# DPHY_RX0_VBUS2APB_WRAP_VBUSP_K3_DPHY_RX register map
Vendor: Texas Instruments
Registers are 32-bit, access per field, reset 0x0 unless marked. A register's access mark holds for its fields unless they carry their own. Offsets are as the file gives them; [hi:lo] are bit positions; {n}, {i} and the like mark numbered series.

## DPHY_RX0_VBUS2APB_WRAP_VBUSP_K3_DPHY_RX (part 2 of 2)
{0x0+4i} DPHY_RX_VBUS2APB_CMN0_CMN_ANA_TBIT{i} rw (i=0..2) — CMN_ANA_TBIT{i}
  [31:0] ANA_TBIT{i} — Analog Test register {i}
0x0C DPHY_RX_VBUS2APB_CMN0_CMN_ANA_TBIT3 ro — CMN_ANA_TBIT3
  [31:0] ANA_TBIT3 — RESERVED
0x10 DPHY_RX_VBUS2APB_CMN0_CMN_ANA_TBIT4 rw — CMN_ANA_TBIT4
  [31:0] ANA_TBIT4 — Analog Test register 4
0x14 DPHY_RX_VBUS2APB_CMN0_CMN_ANA_TBIT5 — CMN_ANA_TBIT5
  [7:0] ANA_TBIT5 rw — Analog Test register 5
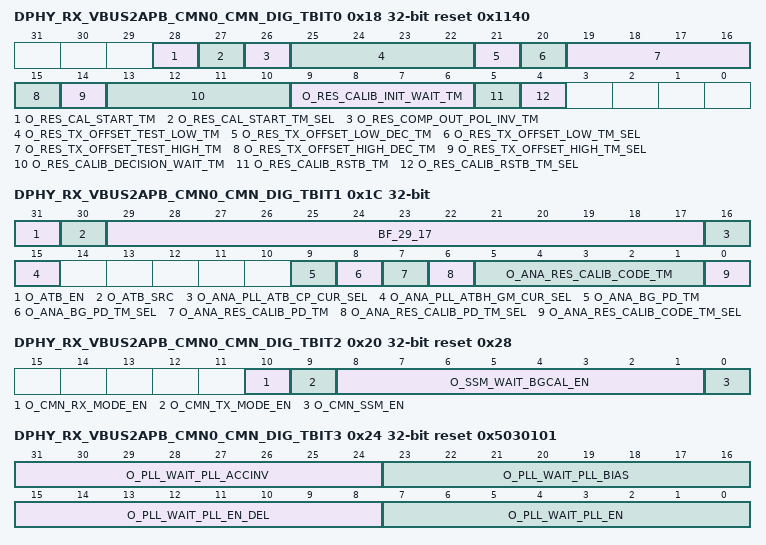
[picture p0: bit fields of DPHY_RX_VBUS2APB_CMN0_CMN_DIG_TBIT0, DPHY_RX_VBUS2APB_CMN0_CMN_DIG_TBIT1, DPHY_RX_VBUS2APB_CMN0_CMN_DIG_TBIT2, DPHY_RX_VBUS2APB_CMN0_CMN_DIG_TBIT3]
0x18 DPHY_RX_VBUS2APB_CMN0_CMN_DIG_TBIT0 reset 0x1140 — CMN_DIG_TBIT0
  [28] O_RES_CAL_START_TM rw — res_cal_start in test mode
  [27] O_RES_CAL_START_TM_SEL rw — res_cal_start select from test_mode
  [26] O_RES_COMP_OUT_POL_INV_TM rw — Invert polarity for resistor calib comparator output
  [25:22] O_RES_TX_OFFSET_TEST_LOW_TM rw — o_res_tx_offset_test_low_TM - Res calib manipulation code for res calib code low
  [21] O_RES_TX_OFFSET_LOW_DEC_TM rw — o_res_tx_offset_low_dec_TM asserted - Perform increment manipulation on res calib code if o_res_tx_offset_low_TM_sel is asserted
  [20] O_RES_TX_OFFSET_LOW_TM_SEL rw — o_res_tx_offset_low_TM_sel asserted - Enable offset manipulation for res calib code low
  [19:16] O_RES_TX_OFFSET_TEST_HIGH_TM rw — o_res_tx_offset_test_high_TM - Res calib manipulation code for res calib code high
  [15] O_RES_TX_OFFSET_HIGH_DEC_TM rw — o_res_tx_offset_high_dec_TM asserted - Perform increment manipulation on res calib code if o_res_tx_offset_high_TM_sel is asserted
  [14] O_RES_TX_OFFSET_HIGH_TM_SEL rw — o_res_tx_offset_high_TM_sel asserted - Enable offset manipulation for res calib code high
  [13:10] O_RES_CALIB_DECISION_WAIT_TM rw — res_calib decision wait time
  [9:6] O_RES_CALIB_INIT_WAIT_TM rw — res_calib initial wait time
  [5] O_RES_CALIB_RSTB_TM rw — w_res_calib_rstb value in testmode
  [4] O_RES_CALIB_RSTB_TM_SEL rw — w_res_calib_rstb select from test_mode
0x1C DPHY_RX_VBUS2APB_CMN0_CMN_DIG_TBIT1 — CMN_DIG_TBIT1
  [31] O_ATB_EN rw — ATB probing enabled
  [30] O_ATB_SRC rw — Select IO for atb probing
  [29:17] BF_29_17 rw
  [16] O_ANA_PLL_ATB_CP_CUR_SEL rw
  [15] O_ANA_PLL_ATBH_GM_CUR_SEL rw
  [9] O_ANA_BG_PD_TM rw — o_ana_bg_pd value in testmode
  [8] O_ANA_BG_PD_TM_SEL rw — o_ana_bg_pd select from test_mode
  [7] O_ANA_RES_CALIB_PD_TM rw — o_ana_res_calib_pd value in testmode
  [6] O_ANA_RES_CALIB_PD_TM_SEL rw — o_ana_res_calib_pd select from test_mode
  [5:1] O_ANA_RES_CALIB_CODE_TM rw — o_ana_res_calib_code value in test_mode
  [0] O_ANA_RES_CALIB_CODE_TM_SEL rw — o_ana_res_calib_code select from test_mode
0x20 DPHY_RX_VBUS2APB_CMN0_CMN_DIG_TBIT2 reset 0x28 — CMN_DIG_TBIT2
  [10] O_CMN_RX_MODE_EN rw — Enable CMN RX related StateMachines
  [9] O_CMN_TX_MODE_EN rw — Enable CMN TX related StateMachines
  [8:1] O_SSM_WAIT_BGCAL_EN rw — Wait time for Calibrations enable after bandgap is enabled [in us]
  [0] O_CMN_SSM_EN rw — Enable CMN startup state machine
0x24 DPHY_RX_VBUS2APB_CMN0_CMN_DIG_TBIT3 rw reset 0x5030101 — CMN_DIG_TBIT3
  [31:24] O_PLL_WAIT_PLL_ACCINV — Wait time in pll_accinv [in us]
  [23:16] O_PLL_WAIT_PLL_BIAS — Wait time in pll_bias [in us]
  [15:8] O_PLL_WAIT_PLL_EN_DEL — Wait time in pll_en_del [in us]
  [7:0] O_PLL_WAIT_PLL_EN — Wait time in PLL en [in us]
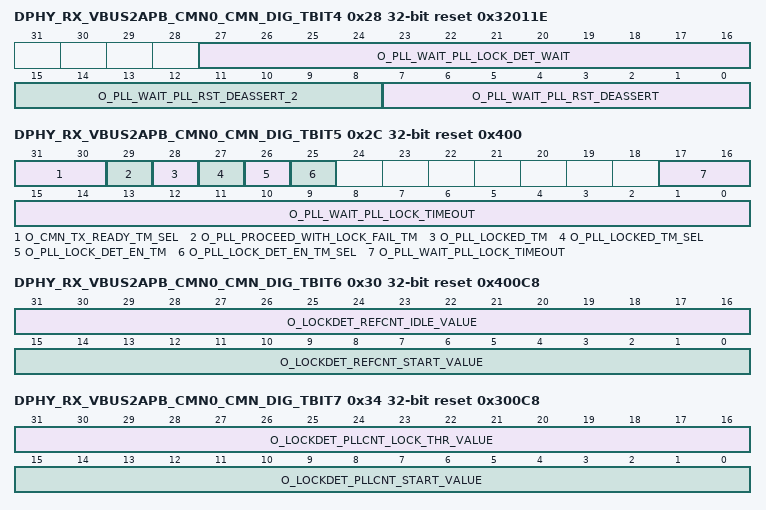
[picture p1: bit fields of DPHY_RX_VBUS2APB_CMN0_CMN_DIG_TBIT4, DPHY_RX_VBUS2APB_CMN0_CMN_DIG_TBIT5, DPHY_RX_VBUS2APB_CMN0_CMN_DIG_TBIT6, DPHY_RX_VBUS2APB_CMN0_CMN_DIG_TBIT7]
0x28 DPHY_RX_VBUS2APB_CMN0_CMN_DIG_TBIT4 reset 0x32011E — CMN_DIG_TBIT4
  [27:16] O_PLL_WAIT_PLL_LOCK_DET_WAIT rw — Wait time in pll_lock_det_wait [in us]
  [15:8] O_PLL_WAIT_PLL_RST_DEASSERT_2 rw — Wait time in pll_rst_deassert_2ndset [in us]
  [7:0] O_PLL_WAIT_PLL_RST_DEASSERT rw — Wait time in pll_rst_deassert [in us]
0x2C DPHY_RX_VBUS2APB_CMN0_CMN_DIG_TBIT5 reset 0x400
  [31:30] O_CMN_TX_READY_TM_SEL rw — ATB probing enabled
  [29] O_PLL_PROCEED_WITH_LOCK_FAIL_TM rw — o_ana_pll_atb_cp_cur_sel
  [28] O_PLL_LOCKED_TM rw — Forced value of pll_locked going to fsm = 1
  [27] O_PLL_LOCKED_TM_SEL rw — pll_locked going to fsm forced from test registers
  [26] O_PLL_LOCK_DET_EN_TM rw — Forced value of pll_lock_det_en = 1
  [25] O_PLL_LOCK_DET_EN_TM_SEL rw — pll_lock_det_en forced from test registers
  [17:0] O_PLL_WAIT_PLL_LOCK_TIMEOUT rw — Wait time for pll_lock_timeout [in us]
0x30 DPHY_RX_VBUS2APB_CMN0_CMN_DIG_TBIT6 rw reset 0x400C8 — CMN_DIG_TBIT6
  [31:16] O_LOCKDET_REFCNT_IDLE_VALUE — refcnt idle value for PLL lock detect module
  [15:0] O_LOCKDET_REFCNT_START_VALUE — refcnt start value for PLL lock detect module
0x34 DPHY_RX_VBUS2APB_CMN0_CMN_DIG_TBIT7 rw reset 0x300C8 — CMN_DIG_TBIT7
  [31:16] O_LOCKDET_PLLCNT_LOCK_THR_VALUE — pllcnt lock threshold value for PLL lock detect module
  [15:0] O_LOCKDET_PLLCNT_START_VALUE — pllcnt start value for PLL lock detect module
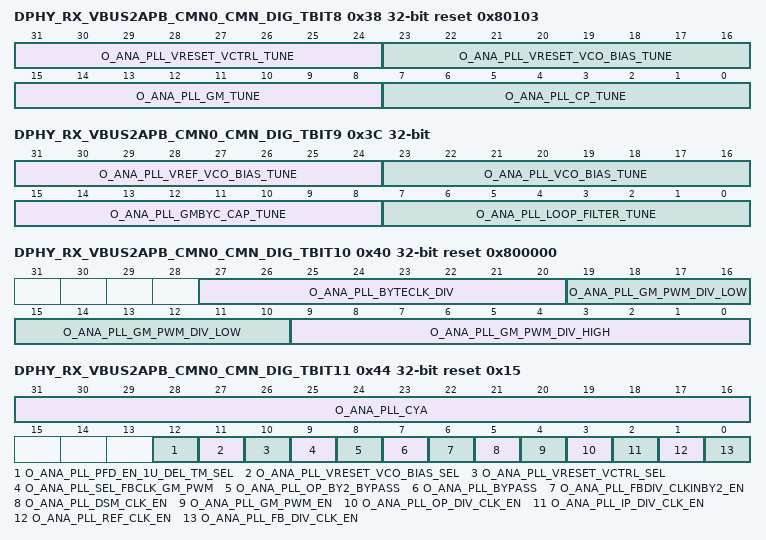
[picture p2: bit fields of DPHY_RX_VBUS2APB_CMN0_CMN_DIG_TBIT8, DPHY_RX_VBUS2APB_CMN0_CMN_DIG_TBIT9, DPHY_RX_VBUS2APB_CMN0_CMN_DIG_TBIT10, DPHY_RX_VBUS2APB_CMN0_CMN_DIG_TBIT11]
0x38 DPHY_RX_VBUS2APB_CMN0_CMN_DIG_TBIT8 rw reset 0x80103 — CMN_DIG_TBIT8
  [31:24] O_ANA_PLL_VRESET_VCTRL_TUNE — unconnected, intended for vreset_vctrl[CP output] progrmmability
  [23:16] O_ANA_PLL_VRESET_VCO_BIAS_TUNE — Programmability for vco bias[gmbyc] initial voltage
  [15:8] O_ANA_PLL_GM_TUNE — gm tune value for PLL
  [7:0] O_ANA_PLL_CP_TUNE — Charge Pump Tune value for PLL
0x3C DPHY_RX_VBUS2APB_CMN0_CMN_DIG_TBIT9 rw — CMN_DIG_TBIT9
  [31:24] O_ANA_PLL_VREF_VCO_BIAS_TUNE — Tuning Control for reference vco bias in PLL
  [23:16] O_ANA_PLL_VCO_BIAS_TUNE — Tuning Control for PLL vco bias
  [15:8] O_ANA_PLL_GMBYC_CAP_TUNE — gmbyc tune value for PLL
  [7:0] O_ANA_PLL_LOOP_FILTER_TUNE — Tuning Control for loop filter
0x40 DPHY_RX_VBUS2APB_CMN0_CMN_DIG_TBIT10 reset 0x800000 — CMN_DIG_TBIT10
  [27:20] O_ANA_PLL_BYTECLK_DIV rw — Byteclk divider value
  [19:10] O_ANA_PLL_GM_PWM_DIV_LOW rw — Low division value setting for the gm PWM control divider
  [9:0] O_ANA_PLL_GM_PWM_DIV_HIGH rw — High division value setting for the gm PWM control divider
0x44 DPHY_RX_VBUS2APB_CMN0_CMN_DIG_TBIT11 reset 0x15 — CMN_DIG_TBIT11
  [31:16] O_ANA_PLL_CYA rw — Drives pllda_cya going to ANA
  [12] O_ANA_PLL_PFD_EN_1U_DEL_TM_SEL rw — Testmode signal for selecting 1us delayed for pll_pfd_reset_n
  [11] O_ANA_PLL_VRESET_VCO_BIAS_SEL rw — vreset_vctrl_gmbyc is set inside the pll_vreset_gen
  [10] O_ANA_PLL_VRESET_VCTRL_SEL rw — vreset_vctrl is set to ground inside the pll_vreset_gen
  [9] O_ANA_PLL_SEL_FBCLK_GM_PWM rw — Enable mode to use feedback clock as the PWM control input for the gm stage
  [8] O_ANA_PLL_OP_BY2_BYPASS rw — Mode to bypass the divide by 2 in the PLL output which generates clk_bit and clk_bitb
  [7] O_ANA_PLL_BYPASS rw — Bypass PLL and pass refclk as output
  [6] O_ANA_PLL_FBDIV_CLKINBY2_EN rw — Enable division by 2 on the feedback divider input clock
  [5] O_ANA_PLL_DSM_CLK_EN rw — Enable for dsm clock output to digital
  [4] O_ANA_PLL_GM_PWM_EN rw — Enable PWM control of the gm, else it will operate in the continuous mode
  [3] O_ANA_PLL_OP_DIV_CLK_EN rw — Enable for op divider clock output to digital
  [2] O_ANA_PLL_IP_DIV_CLK_EN rw — Enable for ip divider output to digital
  [1] O_ANA_PLL_REF_CLK_EN rw — enables refclk to PLL
  [0] O_ANA_PLL_FB_DIV_CLK_EN rw — Enable for feedback clock output to digital
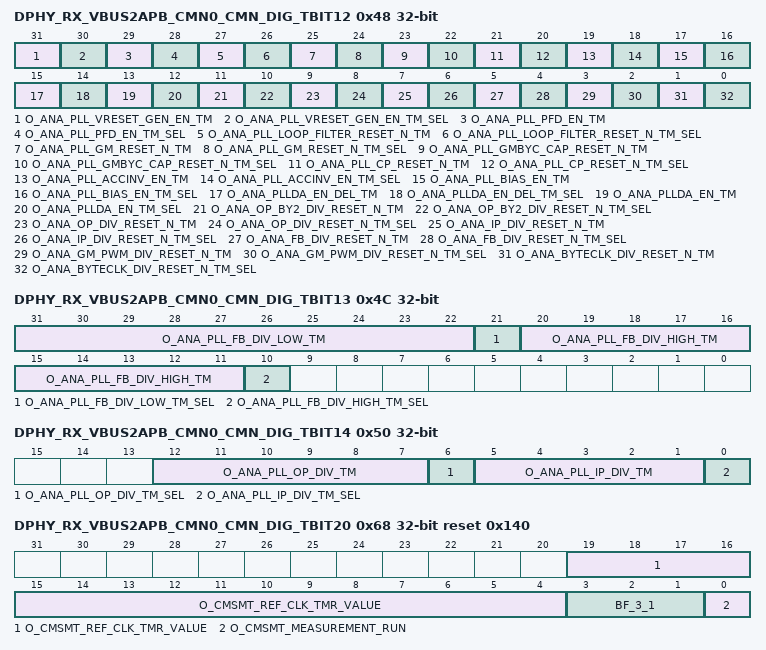
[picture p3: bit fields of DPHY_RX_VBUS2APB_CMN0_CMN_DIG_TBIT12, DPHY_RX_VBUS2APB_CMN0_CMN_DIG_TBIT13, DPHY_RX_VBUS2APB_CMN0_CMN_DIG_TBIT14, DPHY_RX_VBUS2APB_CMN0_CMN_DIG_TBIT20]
0x48 DPHY_RX_VBUS2APB_CMN0_CMN_DIG_TBIT12 rw — CMN_DIG_TBIT12
  [31] O_ANA_PLL_VRESET_GEN_EN_TM — Forced value of pll_vreset_gen_en = 1
  [30] O_ANA_PLL_VRESET_GEN_EN_TM_SEL — pll_vreset_gen_en forced from test registers
  [29] O_ANA_PLL_PFD_EN_TM — Forced value of pllda_pfd_en = 1
  [28] O_ANA_PLL_PFD_EN_TM_SEL — pllda_pfd_en forced from test registers
  [27] O_ANA_PLL_LOOP_FILTER_RESET_N_TM — Forced value of pll_loop_filter_reset_n = 1
  [26] O_ANA_PLL_LOOP_FILTER_RESET_N_TM_SEL — pll_loop_filter_reset_n is drivne from test registers
  [25] O_ANA_PLL_GM_RESET_N_TM — Forced value of pll_gm_reset_n = 1
  [24] O_ANA_PLL_GM_RESET_N_TM_SEL — pll_gm_reset_n is drivne from test registers
  [23] O_ANA_PLL_GMBYC_CAP_RESET_N_TM — Forced value of pll_gmbyc_cap_reset_n = 1
  [22] O_ANA_PLL_GMBYC_CAP_RESET_N_TM_SEL — pll_gmbyc_cap_reset_n is drivne from test registers
  [21] O_ANA_PLL_CP_RESET_N_TM — Forced value of pll_cp_reset_n = 1
  [20] O_ANA_PLL_CP_RESET_N_TM_SEL — pll_cp_reset_n is drivne from test registers
  [19] O_ANA_PLL_ACCINV_EN_TM — Forced value of pllda_accinv = 1
  [18] O_ANA_PLL_ACCINV_EN_TM_SEL — pllda_accinv forced from test registers
  [17] O_ANA_PLL_BIAS_EN_TM — Forced value of pllda_bias_en = 1
  [16] O_ANA_PLL_BIAS_EN_TM_SEL — pllda_bias_en forced from test registers
  [15] O_ANA_PLLDA_EN_DEL_TM — Forced value of pllda_en_del = 1
  [14] O_ANA_PLLDA_EN_DEL_TM_SEL — pllda_en_del forced from test registers
  [13] O_ANA_PLLDA_EN_TM — Forced value of pllda_en_del = 1
  [12] O_ANA_PLLDA_EN_TM_SEL — pllda_en_del forced from test registers
  [11] O_ANA_OP_BY2_DIV_RESET_N_TM — Forced valu of pllda_op_by2_div_reset_n = 1
  [10] O_ANA_OP_BY2_DIV_RESET_N_TM_SEL — pllda_op_by2_div_reset_n forced from test registers
  [9] O_ANA_OP_DIV_RESET_N_TM — Forced value of pllda_op_div_reset_n = 1
  [8] O_ANA_OP_DIV_RESET_N_TM_SEL — pllda_op_div_reset_n forced from test registers
  [7] O_ANA_IP_DIV_RESET_N_TM — Forced value of pllda_ip_div_reset_n = 1
  [6] O_ANA_IP_DIV_RESET_N_TM_SEL — pllda_ip_div_reset_n forced from test registers
  [5] O_ANA_FB_DIV_RESET_N_TM — Forced value of pllda_fb_div_reset_n = 1
  [4] O_ANA_FB_DIV_RESET_N_TM_SEL — pllda_fb_div_reset_n forced from test registers
  [3] O_ANA_GM_PWM_DIV_RESET_N_TM — Forced value of pllda_gm_pwm_div_reset_n = 1
  [2] O_ANA_GM_PWM_DIV_RESET_N_TM_SEL — pllda_gm_pwm_div_reset_n forced from test registers
  [1] O_ANA_BYTECLK_DIV_RESET_N_TM — Forced value of pllda_byteclk_div_reset_n = 1
  [0] O_ANA_BYTECLK_DIV_RESET_N_TM_SEL — pllda_byteclk_div_reset_n forced from test registers
0x4C DPHY_RX_VBUS2APB_CMN0_CMN_DIG_TBIT13 — CMN_DIG_TBIT13
  [31:22] O_ANA_PLL_FB_DIV_LOW_TM rw — forced value for pll_fb_div_clk_low
  [21] O_ANA_PLL_FB_DIV_LOW_TM_SEL rw — pll_fb_div_clk_low forced from test registers
  [20:11] O_ANA_PLL_FB_DIV_HIGH_TM rw — forced value for pll_fb_div_clk_high
  [10] O_ANA_PLL_FB_DIV_HIGH_TM_SEL rw — pll_fb_div_clk_high forced from test registers
0x50 DPHY_RX_VBUS2APB_CMN0_CMN_DIG_TBIT14 — CMN_DIG_TBIT14
  [12:7] O_ANA_PLL_OP_DIV_TM rw — forced value for op_div
  [6] O_ANA_PLL_OP_DIV_TM_SEL rw — op_div forced from test registers
  [5:1] O_ANA_PLL_IP_DIV_TM rw — forced value for ip_div
  [0] O_ANA_PLL_IP_DIV_TM_SEL rw — ip_div forced from test registers
0x68 DPHY_RX_VBUS2APB_CMN0_CMN_DIG_TBIT20 reset 0x140 — CMN_DIG_TBIT20
  [19:4] O_CMSMT_REF_CLK_TMR_VALUE rw — Number of refclk cycles required for clock measurement
  [3:1] BF_3_1 rw
  [0] O_CMSMT_MEASUREMENT_RUN rw — Enables clock measurement
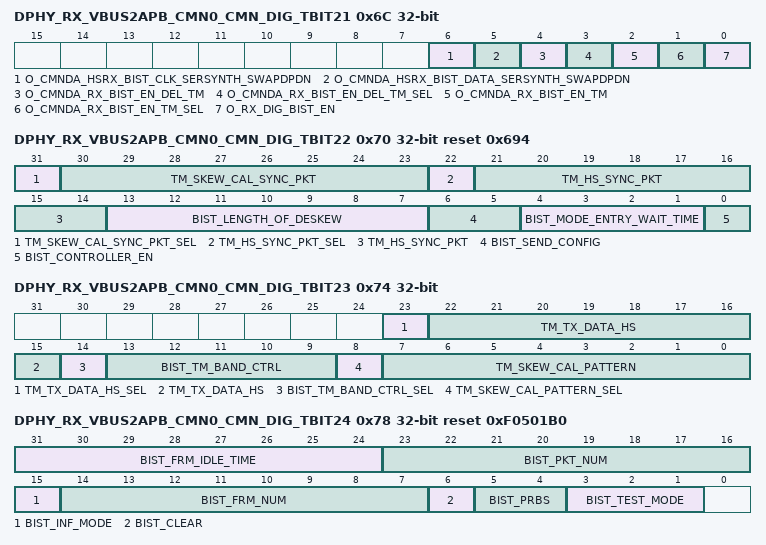
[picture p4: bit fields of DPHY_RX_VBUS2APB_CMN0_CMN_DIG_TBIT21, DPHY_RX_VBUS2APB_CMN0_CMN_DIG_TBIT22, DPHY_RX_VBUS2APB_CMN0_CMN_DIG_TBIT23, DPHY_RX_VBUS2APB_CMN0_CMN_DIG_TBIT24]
0x6C DPHY_RX_VBUS2APB_CMN0_CMN_DIG_TBIT21 — CMN_DIG_TBIT21
  [6] O_CMNDA_HSRX_BIST_CLK_SERSYNTH_SWAPDPDN rw — Enables swapping DP-DN lines for clock bist
  [5] O_CMNDA_HSRX_BIST_DATA_SERSYNTH_SWAPDPDN rw — Enables swapping DP-DN lines for data bist
  [4] O_CMNDA_RX_BIST_EN_DEL_TM rw — forced value of cmnda_rx_bist_en_del = 1
  [3] O_CMNDA_RX_BIST_EN_DEL_TM_SEL rw — cmnda_rx_bist_en_del driven from test registers
  [2] O_CMNDA_RX_BIST_EN_TM rw — forced value of cmnda_rx_bist_en = 1
  [1] O_CMNDA_RX_BIST_EN_TM_SEL rw — cmnda_rx_bist_en driven from test registers
  [0] O_RX_DIG_BIST_EN rw — BIST enable for digital
0x70 DPHY_RX_VBUS2APB_CMN0_CMN_DIG_TBIT22 rw reset 0x694 — BIST_CONFIG_REG1
  [31] TM_SKEW_CAL_SYNC_PKT_SEL — To send 'FF as Skew calibration sync packet
  [30:23] TM_SKEW_CAL_SYNC_PKT — desired skew calibration test sync packet
  [22] TM_HS_SYNC_PKT_SEL — To send 'B8 as HS sync packet
  [21:14] TM_HS_SYNC_PKT — desired HS test sync packet
  [13:7] BIST_LENGTH_OF_DESKEW — Length of deskew sequence In terms of us By default 13us of deskew sequence will be transmitted
  [6:5] BIST_SEND_CONFIG — Option of configuring what to send in BIST mose To send both deskew and HS data
  [4:1] BIST_MODE_ENTRY_WAIT_TIME — Once after giving bist_en signal to pattern generator, after these many number of BYTE clcok cycles pattern generation will start
  [0] BIST_CONTROLLER_EN — Enable BIST controller
0x74 DPHY_RX_VBUS2APB_CMN0_CMN_DIG_TBIT23 — BIST_CONFIG_REG2
  [23] TM_TX_DATA_HS_SEL rw — sends single test byte to sersynth, which is in &lt;
  [22:15] TM_TX_DATA_HS rw — Desired clock patetrn that can be sent using clk_sersynth
  [14] BIST_TM_BAND_CTRL_SEL rw — To take the default band control settigns by the design
  [13:9] BIST_TM_BAND_CTRL rw — Test mode band control setting to be done for BIST
  [8] TM_SKEW_CAL_PATTERN_SEL rw — To send 'AA as skew calibration pattern
  [7:0] TM_SKEW_CAL_PATTERN rw — desired skew calibration test sequence
0x78 DPHY_RX_VBUS2APB_CMN0_CMN_DIG_TBIT24 reset 0xF0501B0 — BIST_CONFIG_REG3
  [31:24] BIST_FRM_IDLE_TIME rw — BIST_FRM_IDLE time is time between the frames
  [23:16] BIST_PKT_NUM rw — BIST_PAK_NUM is number of packets that are to be transmitted per frame
  [15] BIST_INF_MODE rw — run infinite BIST mode
  [14:7] BIST_FRM_NUM rw — BIST_FRM_NUM is number of frames to be transmitted
  [6] BIST_CLEAR rw — clear the bist
  [5:4] BIST_PRBS rw — BIST PRBS MODE 9
  [3:1] BIST_TEST_MODE rw — PRBS mode
0x7C DPHY_RX_VBUS2APB_CMN0_CMN_DIG_TBIT25 reset 0x28 — BIST_CONFIG_REG4
  [11:0] BIST_RUN_LENGTH rw
0x80 DPHY_RX_VBUS2APB_CMN0_CMN_DIG_TBIT26 reset 0xA — BIST_CONFIG_REG5
  [7:0] BIST_IDLE_TIME rw
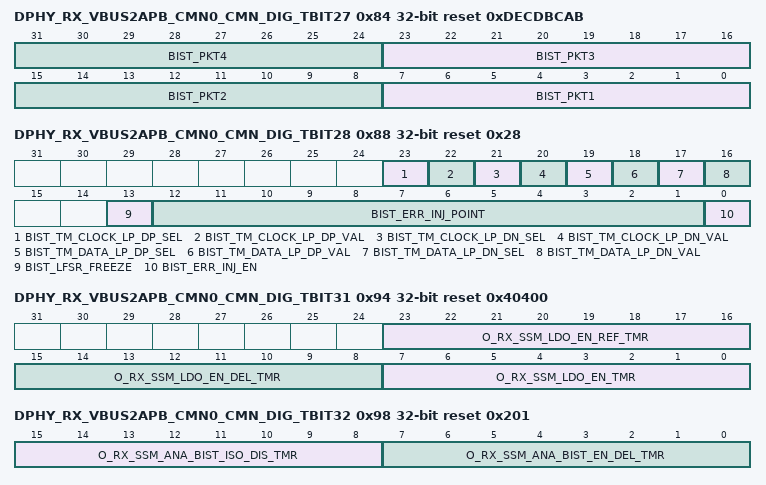
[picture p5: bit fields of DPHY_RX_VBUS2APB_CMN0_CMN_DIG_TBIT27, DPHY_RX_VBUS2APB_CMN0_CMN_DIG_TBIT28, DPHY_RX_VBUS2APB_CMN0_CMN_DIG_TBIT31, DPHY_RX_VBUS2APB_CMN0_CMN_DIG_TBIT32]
0x84 DPHY_RX_VBUS2APB_CMN0_CMN_DIG_TBIT27 rw reset 0xDECDBCAB — BIST_CONFIG_REG6
  [8n-1:8n-8] BIST_PKT{n} (n=1..4) — BIST_TEST_PAT{n}
0x88 DPHY_RX_VBUS2APB_CMN0_CMN_DIG_TBIT28 reset 0x28 — BIST_CONFIG_REG7
  [23] BIST_TM_CLOCK_LP_DP_SEL rw — Test mode selection bit to force clcok LP DP buffer to value from design
  [22] BIST_TM_CLOCK_LP_DP_VAL rw — Test mode clock LP DP buffer value is 0
  [21] BIST_TM_CLOCK_LP_DN_SEL rw — Test mode selection bit to force clcok LP DN buffer to value from design
  [20] BIST_TM_CLOCK_LP_DN_VAL rw — Test mode clock LP DN buffer value is 0
  [19] BIST_TM_DATA_LP_DP_SEL rw — Test mode selection bit to force data LP DP buffer to value from design
  [18] BIST_TM_DATA_LP_DP_VAL rw — Test mode data LP DP buffer value is 0
  [17] BIST_TM_DATA_LP_DN_SEL rw — Test mode selection bit to force data LP DN buffer to value from design
  [16] BIST_TM_DATA_LP_DN_VAL rw — Test mode data LP DN buffer value is 0
  [13] BIST_LFSR_FREEZE rw — Reset LFSR contents after every packet or frame
  [12:1] BIST_ERR_INJ_POINT rw — BIST_ERR_INJECT_POINT is where to inject the error in the packet
  [0] BIST_ERR_INJ_EN rw — Inject error in the BIST during the packet
0x94 DPHY_RX_VBUS2APB_CMN0_CMN_DIG_TBIT31 reset 0x40400 — CMN_DIG_TBIT31
  [23:16] O_RX_SSM_LDO_EN_REF_TMR rw — Wait time before enabling oscialltor calibration
  [15:8] O_RX_SSM_LDO_EN_DEL_TMR rw — wait time before enabling ldo_en_ref
  [7:0] O_RX_SSM_LDO_EN_TMR rw — Wait time between ldo_en and ldo_en_del
0x98 DPHY_RX_VBUS2APB_CMN0_CMN_DIG_TBIT32 reset 0x201 — CMN_DIG_TBIT32
  [15:8] O_RX_SSM_ANA_BIST_ISO_DIS_TMR rw — Wait time between Bist_en_del and disabling isolation
  [7:0] O_RX_SSM_ANA_BIST_EN_DEL_TMR rw — Wait time between Bist_en and bist_en_Del
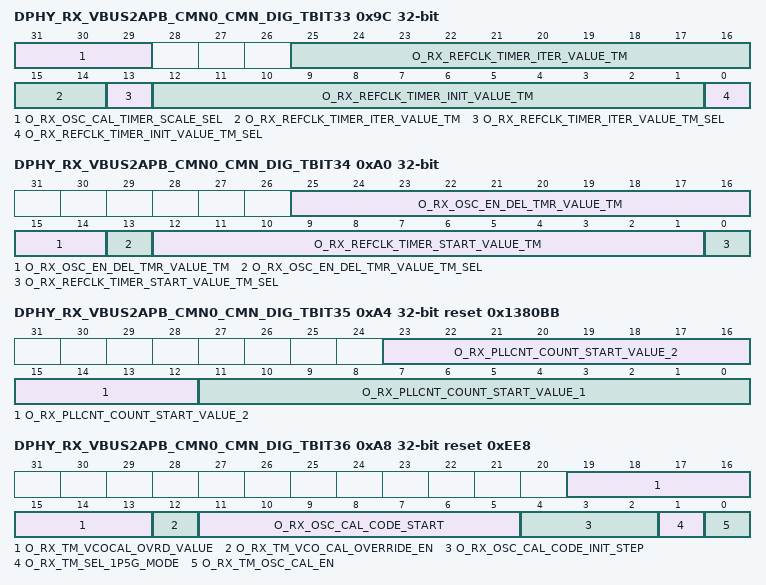
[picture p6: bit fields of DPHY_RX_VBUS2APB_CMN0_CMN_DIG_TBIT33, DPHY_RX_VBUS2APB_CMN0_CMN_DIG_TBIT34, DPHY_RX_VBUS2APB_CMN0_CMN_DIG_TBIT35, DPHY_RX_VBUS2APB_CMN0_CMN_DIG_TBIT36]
0x9C DPHY_RX_VBUS2APB_CMN0_CMN_DIG_TBIT33 — CMN_DIG_TBIT33
  [31:29] O_RX_OSC_CAL_TIMER_SCALE_SEL rw — Timer scale value for vco_count_window
  [25:14] O_RX_REFCLK_TIMER_ITER_VALUE_TM rw — Wait time required before enabling vco count window during iteration in test mode
  [13] O_RX_REFCLK_TIMER_ITER_VALUE_TM_SEL rw — refclk_timer_iter value driven from test register
  [12:1] O_RX_REFCLK_TIMER_INIT_VALUE_TM rw — Wait time required before enabling vco count window in initial phase in test mode
  [0] O_RX_REFCLK_TIMER_INIT_VALUE_TM_SEL rw — refclk_timer_init value driven from test register
0xA0 DPHY_RX_VBUS2APB_CMN0_CMN_DIG_TBIT34 — CMN_DIG_TBIT34
  [25:14] O_RX_OSC_EN_DEL_TMR_VALUE_TM rw — Wait time between osc_en and osc_en_del in Test mode
  [13] O_RX_OSC_EN_DEL_TMR_VALUE_TM_SEL rw — osc_en_del_tmr driven from test register
  [12:1] O_RX_REFCLK_TIMER_START_VALUE_TM rw — No of refclk cycles required for single vco count window in test mode
  [0] O_RX_REFCLK_TIMER_START_VALUE_TM_SEL rw — refclk_timer_start_value driven from test mode
0xA4 DPHY_RX_VBUS2APB_CMN0_CMN_DIG_TBIT35 reset 0x1380BB — CMN_DIG_TBIT35
  [23:12] O_RX_PLLCNT_COUNT_START_VALUE_2 rw — No of PLL clock cycles expected in 25G mode
  [11:0] O_RX_PLLCNT_COUNT_START_VALUE_1 rw — No of PLL clock cycles expected in 15G mode
0xA8 DPHY_RX_VBUS2APB_CMN0_CMN_DIG_TBIT36 reset 0xEE8 — CMN_DIG_TBIT36
  [19:13] O_RX_TM_VCOCAL_OVRD_VALUE rw — Vco calcode Test mode value
  [12] O_RX_TM_VCO_CAL_OVERRIDE_EN rw — Enables test mode overwrite for vco cal code
  [11:5] O_RX_OSC_CAL_CODE_START rw — Starting code for vco calibration
  [4:2] O_RX_OSC_CAL_CODE_INIT_STEP rw — Step size for incrmenting vco cal code
  [1] O_RX_TM_SEL_1P5G_MODE rw — Select 1p5g mode oscillator clock
  [0] O_RX_TM_OSC_CAL_EN rw — Test mode overwrite for crude osc calibration enable
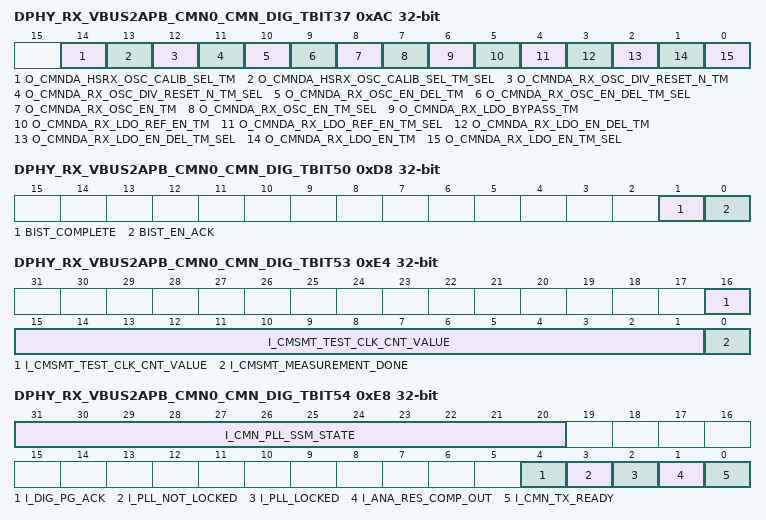
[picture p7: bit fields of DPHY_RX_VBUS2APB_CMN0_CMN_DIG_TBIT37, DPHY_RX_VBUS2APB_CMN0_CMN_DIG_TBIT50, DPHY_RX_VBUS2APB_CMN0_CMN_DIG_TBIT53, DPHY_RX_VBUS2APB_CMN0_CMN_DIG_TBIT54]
0xAC DPHY_RX_VBUS2APB_CMN0_CMN_DIG_TBIT37
  [14] O_CMNDA_HSRX_OSC_CALIB_SEL_TM rw — forced value of hsrx_osc_calib_sel = 1
  [13] O_CMNDA_HSRX_OSC_CALIB_SEL_TM_SEL rw — hsrx_osc_calib_sel driven from test registers
  [12] O_CMNDA_RX_OSC_DIV_RESET_N_TM rw — forced value of rx_osc_div_reset_n = 1
  [11] O_CMNDA_RX_OSC_DIV_RESET_N_TM_SEL rw — rx_osc_div_reset_n driven from test registers
  [10] O_CMNDA_RX_OSC_EN_DEL_TM rw — forced value of rx_osc_en_del = 1
  [9] O_CMNDA_RX_OSC_EN_DEL_TM_SEL rw — rx_osc_en_del driven from test registers
  [8] O_CMNDA_RX_OSC_EN_TM rw — forced value of rx_osc_en = 1
  [7] O_CMNDA_RX_OSC_EN_TM_SEL rw — rx_osc_en driven from test registers
  [6] O_CMNDA_RX_LDO_BYPASS_TM rw — Bypass LDO in test mode
  [5] O_CMNDA_RX_LDO_REF_EN_TM rw — forced value of rx_ldo_ref_en = 1
  [4] O_CMNDA_RX_LDO_REF_EN_TM_SEL rw — rx_ldo_ref_en driven from test registers
  [3] O_CMNDA_RX_LDO_EN_DEL_TM rw — forced value of rx_ldo_en_del = 1
  [2] O_CMNDA_RX_LDO_EN_DEL_TM_SEL rw — rx_ldo_en_del driven from test registers
  [1] O_CMNDA_RX_LDO_EN_TM rw — forced value of rx_ldo_en = 1
  [0] O_CMNDA_RX_LDO_EN_TM_SEL rw — rx_ldo_en driven from test registers
0xB0 DPHY_RX_VBUS2APB_CMN0_CMN_DIG_TBIT38 ro — CMN_DIG_TBIT38
0xB4 DPHY_RX_VBUS2APB_CMN0_CMN_DIG_TBIT39 rw — CMN_DIG_TBIT39
  [31:0] SPARE
0xD8 DPHY_RX_VBUS2APB_CMN0_CMN_DIG_TBIT50 ro — BIST_STATUS_REG1
  [1] BIST_COMPLETE — BIST is completed
  [0] BIST_EN_ACK — BIST Controller is enabled
0xE4 DPHY_RX_VBUS2APB_CMN0_CMN_DIG_TBIT53 ro — CMN_DIG_TBIT53
  [16:1] I_CMSMT_TEST_CLK_CNT_VALUE — Gives clocks cycles count for test clock during measurement
  [0] I_CMSMT_MEASUREMENT_DONE — Indicates clock measurement is done
0xE8 DPHY_RX_VBUS2APB_CMN0_CMN_DIG_TBIT54 ro — CMN_DIG_TBIT54
  [31:20] I_CMN_PLL_SSM_STATE — Gives CMN PLL ssm state
  [4] I_DIG_PG_ACK — PSM power good acknowledgement
  [3] I_PLL_NOT_LOCKED — Indicates PLL is not locked before timeout
  [2] I_PLL_LOCKED — Indicates PLL is locked
  [1] I_ANA_RES_COMP_OUT — read value of comaprator output
  [0] I_CMN_TX_READY — Indiacates cmn is ready for TX IP
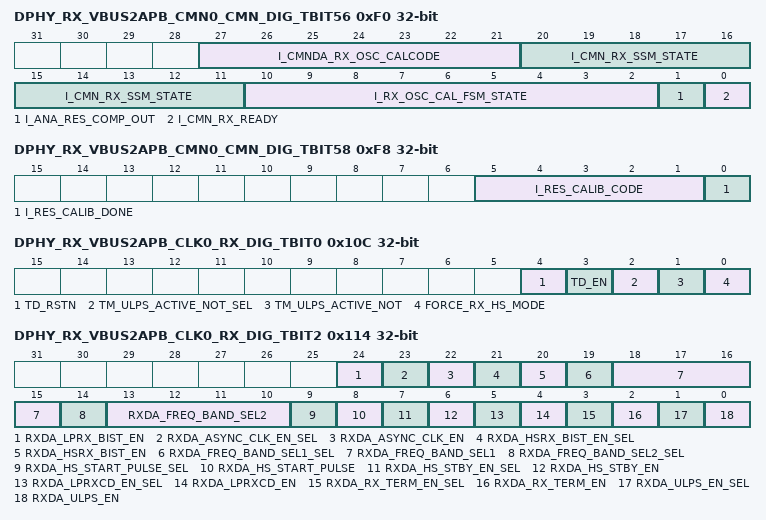
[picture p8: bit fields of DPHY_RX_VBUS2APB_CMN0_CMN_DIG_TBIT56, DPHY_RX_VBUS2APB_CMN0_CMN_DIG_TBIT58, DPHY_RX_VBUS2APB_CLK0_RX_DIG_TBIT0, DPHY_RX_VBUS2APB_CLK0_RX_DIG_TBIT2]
0xF0 DPHY_RX_VBUS2APB_CMN0_CMN_DIG_TBIT56 ro — CMN_DIG_TBIT56
  [27:21] I_CMNDA_RX_OSC_CALCODE — Reads out calib code applied to osicllator
  [20:11] I_CMN_RX_SSM_STATE — Gives CMN Rx ssm state
  [10:2] I_RX_OSC_CAL_FSM_STATE — Gives Rx osc calib FSM state
  [1] I_ANA_RES_COMP_OUT — read value of comaprator output
  [0] I_CMN_RX_READY — Indicates cmn is ready for RX IP
0xF8 DPHY_RX_VBUS2APB_CMN0_CMN_DIG_TBIT58 ro — CMN_DIG_TBIT58
  [5:1] I_RES_CALIB_CODE — Gives out calibrated resistor calibration code
  [0] I_RES_CALIB_DONE — Indicates resistor calibration is done
0x100 DPHY_RX_VBUS2APB_CLK0_RX_ANA_TBIT0 rw — Analog Test Bit Reg0
  [31:0] ANA_TBIT0 — Analog Test Register 0
0x104 DPHY_RX_VBUS2APB_CLK0_RX_ANA_TBIT1 rw — Analog Test Bit Reg1
  [31:0] ANA_TBIT1 — Analog Test Register 1
0x108 DPHY_RX_VBUS2APB_CLK0_RX_ANA_TBIT2 ro — Analog Test Bit Reg2
  [31:0] ANA_TBIT2 — RESERVED
0x10C DPHY_RX_VBUS2APB_CLK0_RX_DIG_TBIT0 — Digital Test Bit Reg0
  [4] TD_RSTN rw — TD is reset - Active low reset control to 'transition_detector_logic'
  [3] TD_EN rw — TD is ENABLED - Active high control to enable 'transition_detector_logic'
  [2] TM_ULPS_ACTIVE_NOT_SEL rw — Power suspend request in ULPS mode through a test register bypassed with a test value via bit-1 here
  [1] TM_ULPS_ACTIVE_NOT rw — When want to control the ULPS mode power suspend request by test register, what should be the value -
  [0] FORCE_RX_HS_MODE rw — Set this bit to force the CRX into HS mode
0x110 DPHY_RX_VBUS2APB_CLK0_RX_DIG_TBIT1 rw — Digital Extra Test Bit Reg0
  [31:0] DIG_EXTRA_TBIT0 — Digital Extra Test Register 0
0x114 DPHY_RX_VBUS2APB_CLK0_RX_DIG_TBIT2 — Test Mux Register
  [24] RXDA_LPRX_BIST_EN rw — LP BIST ENABLED
  [23] RXDA_ASYNC_CLK_EN_SEL rw — rxda_async_clk_en_sel - Controls the selection on clock 'Gate-en' for allowing HS-DDR clock onto Aanlog Interface with options being the funtional mode or from Register-bit
  [22] RXDA_ASYNC_CLK_EN rw — rxda_async_clk_en - 'Gate_en' value to be considered when choosen to take the value through software way when [23] here is set
  [21] RXDA_HSRX_BIST_EN_SEL rw — rxda_hsrx_bist_en_sel - Select signal to choose between functional 'bist_en' from top-level [or] from software register
  [20] RXDA_HSRX_BIST_EN rw — rxda_hsrx_bist_en - value to be considered when choosen to take the value through software way
  [19] RXDA_FREQ_BAND_SEL1_SEL rw — rxda_freq_band_sel1_sel - Select signal to choose between functional 'freq_band' from top-level [or] from software register
  [18:15] RXDA_FREQ_BAND_SEL1 rw — rxda_freq_band_sel
  [14] RXDA_FREQ_BAND_SEL2_SEL rw — rxda_freq_band_sel2_sel - Select signal to choose between functional 'freq_band' from top-level [or] from software register
  [13:10] RXDA_FREQ_BAND_SEL2 rw — rxda_freq_band_sel
  [9] RXDA_HS_START_PULSE_SEL rw — rxda_hs_start_pulse_sel - Select signal to choose between functional 'start_pulse' [or] from software register
  [8] RXDA_HS_START_PULSE rw — rxda_hs_start_pulse - 'start_pulse' value considered when selected to have it via software way
  [7] RXDA_HS_STBY_EN_SEL rw — rxda_hs_stby_en_sel - Select signal to choose between functional 'stby_en' [or] from software register
  [6] RXDA_HS_STBY_EN rw — rxda_hs_stby_en - 'stby_en' value considered when selected to have it via software way
  [5] RXDA_LPRXCD_EN_SEL rw — rxda_lprxcd_en_sel - Select signal to choose between functional 'lprxcd_en' [or] from software register
  [4] RXDA_LPRXCD_EN rw — rxda_lprxcd_en - 'lprxcd_en' value considered when selected to have it via software way
  [3] RXDA_RX_TERM_EN_SEL rw — rxda_rx_term_en_sel - Select signal to choose between functional 'term_en' [or] from software register
  [2] RXDA_RX_TERM_EN rw — rxda_rx_term_en - 'term_en' value considered when selected to have it via software way
  [1] RXDA_ULPS_EN_SEL rw — rxda_ulps_en_sel - Select signal to choose between functional 'ulps_en' [or] from software register
  [0] RXDA_ULPS_EN rw — rxda_ulps_en - 'ulps_en' value considered when selected to have it via software way
0x118 DPHY_RX_VBUS2APB_CLK0_RX_DIG_TBIT3 ro — Digital Extra Test Bit Reg1
  [31:0] DIG_EXTRA_TBIT1 — RESERVED
0x11C DPHY_RX_VBUS2APB_CLK0_RX_ANA_TBIT3 ro — Analog Read Test Bit Reg3
  [31:0] ANA_READ_TBIT3 — Analog read register 3
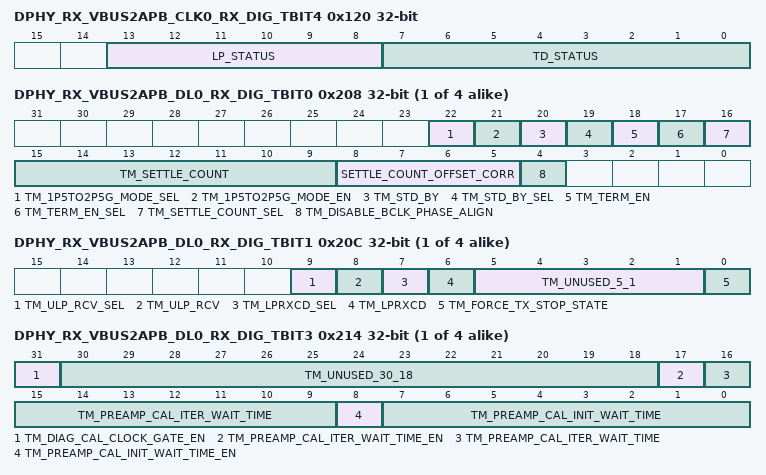
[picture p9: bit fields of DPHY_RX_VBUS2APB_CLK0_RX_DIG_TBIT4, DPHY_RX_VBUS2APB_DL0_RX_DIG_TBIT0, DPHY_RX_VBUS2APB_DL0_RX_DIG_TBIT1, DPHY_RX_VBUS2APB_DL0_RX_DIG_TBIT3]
0x120 DPHY_RX_VBUS2APB_CLK0_RX_DIG_TBIT4 ro — Digital Read Test Reg0
  [13:8] LP_STATUS — Status of DP,DN pins of LPRX, LPCD, ULPRX respectively
  [7:0] TD_STATUS — Posedge and Negedge transition detect status of LPRX_DP, LPRX_DN, LPCD_DP, LPCD_DN
0x124 DPHY_RX_VBUS2APB_CLK0_RX_DIG_TBIT5 ro — Digital Read Test Bit Reg0
  [31:0] DIG_READ_EXTRA_TBIT0 — RESERVED
0x128 DPHY_RX_VBUS2APB_CLK0_RX_DIG_TBIT6 ro — BIST Status Reg0
0x12C DPHY_RX_VBUS2APB_CLK0_RX_DIG_TBIT7 ro — Bist Extra Status Read Reg0
  [31:0] DIG_BIST_READ_EXTRA_TBIT0 — RESERVED
0x130 DPHY_RX_VBUS2APB_CLK0_RX_DIG_TBIT8 ro — Digital Extra Read Reg0
  [31:0] DIG_READ_TBIT1 — RESERVED
{0x200+0x100*i} DPHY_RX_VBUS2APB_DL{i}_RX_ANA_TBIT0 rw (i=0..3) — ANA_TBIT0
  [31:0] ANA_TBIT0 — Analog Test register 0
{0x204+0x100*i} DPHY_RX_VBUS2APB_DL{i}_RX_ANA_TBIT1 ro (i=0..3) — ANA_EXTRA_TBIT0
  [31:0] ANA_EXTRA_TBIT0 — RESERVED
{0x208+0x100*i} DPHY_RX_VBUS2APB_DL{i}_RX_DIG_TBIT0 (i=0..3) — DIG_TBIT0
  [22] TM_1P5TO2P5G_MODE_SEL rw — w_tm_1p5to2p5g_mode_sel - Select signal to choose 'mode_en' based on top-level 'bandctrl' input provided [or] from software register
  [21] TM_1P5TO2P5G_MODE_EN rw — w_tm_1p5to2p5g_mode_en - 'mode_en' value considered when selected to have it via software way
  [20] TM_STD_BY rw — w_tm_std_by - 'tm_std_by' value to be considered when selected to have it via software way Part of control logic to initiate movement of 'calib_ctrl' FSM
  [19] TM_STD_BY_SEL rw — w_tm_std_by_sel - Select signal to choose between functional 'tm_std_by' [or] from software register
  [18] TM_TERM_EN rw — w_tm_term_en - 'tm_term_en' value to be considered when selected to have it via software way Value provided here converges onto 'rxda_rx_term_en' pin on alalog interface
  [17] TM_TERM_EN_SEL rw — w_tm_term_en_sel - Select signal to choose between functional 'term_en_sel' [or] from software register
  [16] TM_SETTLE_COUNT_SEL rw — Test mode settle count selection =
  [15:9] TM_SETTLE_COUNT rw — Test mode settle count, if bit &lt;16&gt; is set - 'settle_count' value to be considered when selected to have it via software way
  [8:5] SETTLE_COUNT_OFFSET_CORR rw — Settle count offset correction value that adds up to the internal predifined settle count based on 'BandCtl' which helps in deciding the final 'settle_count' to be observed for
  [4] TM_DISABLE_BCLK_PHASE_ALIGN rw — test mode to disable byte clock phase alignment
{0x20C+0x100*i} DPHY_RX_VBUS2APB_DL{i}_RX_DIG_TBIT1 (i=0..3) — DIG_TBIT1
  [9] TM_ULP_RCV_SEL rw — w_tm_ulp_rcv_sel - Select signal to choose between functional 'ulp_rcv_en' or a value from software register The effective value converges onto port 'i_ana_ulps_rcv_en' of 'lane_always_on' block at DPHY_RX_VBUS2APB_LANE-level
  [8] TM_ULP_RCV rw — w_tm_ulp_rcv_en - 'ulp_rcv_en' value considered when selected to have it via software way
  [7] TM_LPRXCD_SEL rw — w_tm_lprxcd_sel - Select signal to choose the lprxcd's block enable value to analog between the one from 'lane_always_on' or from the software way onto the port 'rxda_lprxcd_en' on Analog interface
  [6] TM_LPRXCD rw — w_tm_lprxcd_en - 'lprxcd_en' value considered when selected to have it via software way
  [5:1] TM_UNUSED_5_1 ro — RESERVED
  [0] TM_FORCE_TX_STOP_STATE rw — 0' - No force on escape mode logic - Check polarity
{0x210+0x100*i} DPHY_RX_VBUS2APB_DL{i}_RX_DIG_TBIT2 rw (i=0..3) — DIGITAL_EXTRA_TEST_REG0
  [31:0] DIG_EXTRA_TEST_REG0 — Digital Extra Functional Test Register 0
{0x214+0x100*i} DPHY_RX_VBUS2APB_DL{i}_RX_DIG_TBIT3 (i=0..3) — preamp_cal_ctrl_reg1
  [31] TM_DIAG_CAL_CLOCK_GATE_EN rw — While running diagnostic calibrations, this acts as calibration's clock gate enable Enable = 1
  [30:18] TM_UNUSED_30_18 ro — RESERVED
  [17] TM_PREAMP_CAL_ITER_WAIT_TIME_EN rw — test mode wait time between two codes selection
  [16:9] TM_PREAMP_CAL_ITER_WAIT_TIME rw — test mode wait time between two codes
  [8] TM_PREAMP_CAL_INIT_WAIT_TIME_EN rw — test mode initial wait time selection - Select signal to choose between the one from software way or the functional one Functional value gets decided internally based on the 'psm_clock_freq' input to Data-Lane
  [7:0] TM_PREAMP_CAL_INIT_WAIT_TIME rw — test mode initial wait time - 'init_value' considered when selected to choose it via software way
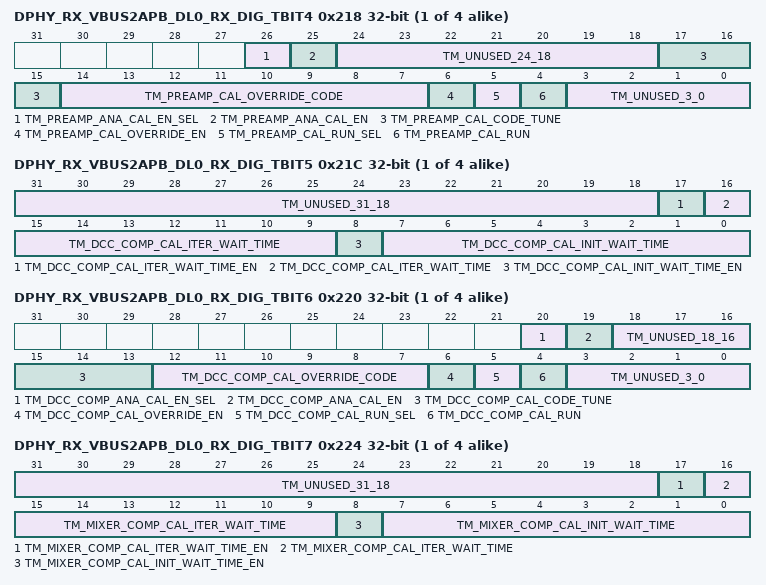
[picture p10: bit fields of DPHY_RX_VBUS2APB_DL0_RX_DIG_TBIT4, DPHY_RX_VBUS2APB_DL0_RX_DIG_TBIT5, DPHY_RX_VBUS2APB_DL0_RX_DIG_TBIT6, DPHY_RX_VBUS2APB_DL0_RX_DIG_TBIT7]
{0x218+0x100*i} DPHY_RX_VBUS2APB_DL{i}_RX_DIG_TBIT4 (i=0..3) — preamp_cal_ctrl_reg2
  [26] TM_PREAMP_ANA_CAL_EN_SEL rw — take analog calib en from logic or test reg
  [25] TM_PREAMP_ANA_CAL_EN rw — test mode analog calibration enable
  [24:18] TM_UNUSED_24_18 ro — RESERVED
  [17:15] TM_PREAMP_CAL_CODE_TUNE rw — final preamp cal code tune value
  [14:7] TM_PREAMP_CAL_OVERRIDE_CODE rw — preamp calibration override code
  [6] TM_PREAMP_CAL_OVERRIDE_EN rw — preamp calibration code override enable
  [5] TM_PREAMP_CAL_RUN_SEL rw — test mode calibration run selection
  [4] TM_PREAMP_CAL_RUN rw — test mode calibration run
  [3:0] TM_UNUSED_3_0 ro — RESERVED
{0x21C+0x100*i} DPHY_RX_VBUS2APB_DL{i}_RX_DIG_TBIT5 (i=0..3) — dcc_comp_cal_ctrl_reg1
  [31:18] TM_UNUSED_31_18 ro — RESERVED
  [17] TM_DCC_COMP_CAL_ITER_WAIT_TIME_EN rw — test mode dcc comp calibration itertaion time enable
  [16:9] TM_DCC_COMP_CAL_ITER_WAIT_TIME rw — test mode dcc comp calibration iteration time
  [8] TM_DCC_COMP_CAL_INIT_WAIT_TIME_EN rw — test mode dcc comp calibration initial wait time enable
  [7:0] TM_DCC_COMP_CAL_INIT_WAIT_TIME rw — test mode dcc comp calibration initial wait time
{0x220+0x100*i} DPHY_RX_VBUS2APB_DL{i}_RX_DIG_TBIT6 (i=0..3) — dcc_comp_cal_ctrl_reg2
  [20] TM_DCC_COMP_ANA_CAL_EN_SEL rw — take analog calib en from logic or test reg
  [19] TM_DCC_COMP_ANA_CAL_EN rw — test mode dcc comp cal analog enable
  [18:16] TM_UNUSED_18_16 ro — RESERVED
  [15:13] TM_DCC_COMP_CAL_CODE_TUNE rw — test mode dcc comp calibration code tune value
  [12:7] TM_DCC_COMP_CAL_OVERRIDE_CODE rw — test mode dcc comp calibration code overirde
  [6] TM_DCC_COMP_CAL_OVERRIDE_EN rw — test mode dcc comp calibration override code enable
  [5] TM_DCC_COMP_CAL_RUN_SEL rw — dcc comp calibration run selection
  [4] TM_DCC_COMP_CAL_RUN rw — dcc comp calibration test mode run
  [3:0] TM_UNUSED_3_0 ro — RESERVED
{0x224+0x100*i} DPHY_RX_VBUS2APB_DL{i}_RX_DIG_TBIT7 (i=0..3) — mix_comp_cal_ctrl_reg1
  [31:18] TM_UNUSED_31_18 ro — RESERVED
  [17] TM_MIXER_COMP_CAL_ITER_WAIT_TIME_EN rw — test mode mixer comp calibration itertaion time enable
  [16:9] TM_MIXER_COMP_CAL_ITER_WAIT_TIME rw — test mode mixer comp calibration iteration time
  [8] TM_MIXER_COMP_CAL_INIT_WAIT_TIME_EN rw — test mode mixer comp calibration initial wait time enable
  [7:0] TM_MIXER_COMP_CAL_INIT_WAIT_TIME rw — test mode mixer comp calibration initial wait time
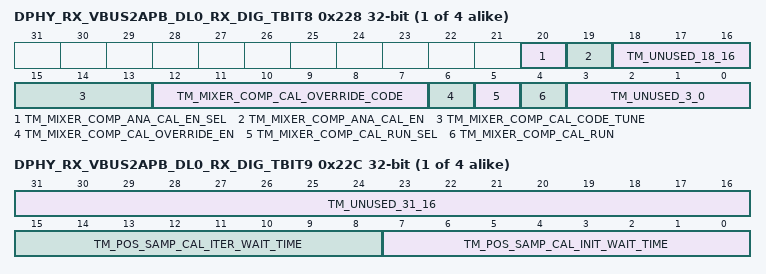
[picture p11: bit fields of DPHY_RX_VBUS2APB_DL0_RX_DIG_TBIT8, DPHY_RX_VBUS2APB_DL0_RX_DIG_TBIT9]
{0x228+0x100*i} DPHY_RX_VBUS2APB_DL{i}_RX_DIG_TBIT8 (i=0..3) — mix_comp_cal_ctrl_reg2
  [20] TM_MIXER_COMP_ANA_CAL_EN_SEL rw — take analog calib en from logic or test reg
  [19] TM_MIXER_COMP_ANA_CAL_EN rw — test mode mixer comp cal analog enable
  [18:16] TM_UNUSED_18_16 ro — RESERVED
  [15:13] TM_MIXER_COMP_CAL_CODE_TUNE rw — test mode mixer comp calibration code tune value
  [12:7] TM_MIXER_COMP_CAL_OVERRIDE_CODE rw — test mode mixer comp calibration code overirde
  [6] TM_MIXER_COMP_CAL_OVERRIDE_EN rw — test mode mixer comp calibration override code enable
  [5] TM_MIXER_COMP_CAL_RUN_SEL rw — mixer comp calibration run selection
  [4] TM_MIXER_COMP_CAL_RUN rw — mixer comp calibration test mode run
  [3:0] TM_UNUSED_3_0 ro — RESERVED
{0x22C+0x100*i} DPHY_RX_VBUS2APB_DL{i}_RX_DIG_TBIT9 (i=0..3) — pos_samp_cal_ctrl_reg1
  [31:16] TM_UNUSED_31_16 ro — RESERVED
  [15:8] TM_POS_SAMP_CAL_ITER_WAIT_TIME rw — posedge sampler calibration ieration time between codes
  [7:0] TM_POS_SAMP_CAL_INIT_WAIT_TIME rw — posedge sampler calibration initial wait time
